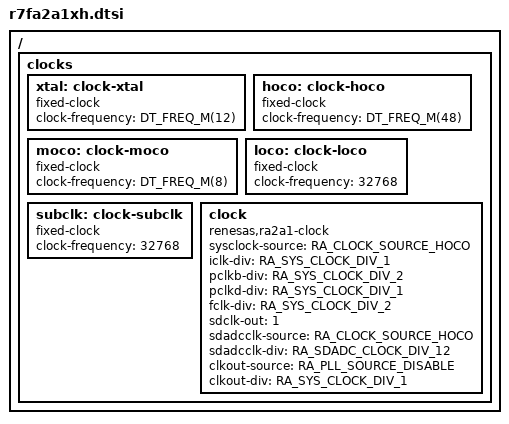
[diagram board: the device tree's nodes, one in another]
/*
 * Copyright (c) 2024 TOKITA Hiroshi
 *
 * SPDX-License-Identifier: Apache-2.0
 */

#include <zephyr/dt-bindings/clock/ra_clock.h>
#include <renesas/ra/ra2/ra2xx.dtsi>

/delete-node/ &sci2;
/delete-node/ &sci3;
/delete-node/ &gpio6;
/delete-node/ &gpio7;
/delete-node/ &gpio8;

/ {
	clocks {
		xtal: clock-xtal {
			compatible = "fixed-clock";
			clock-frequency = <DT_FREQ_M(12)>;
			#clock-cells = <0>;
		};

		hoco: clock-hoco {
			compatible = "fixed-clock";
			clock-frequency = <DT_FREQ_M(48)>;
			#clock-cells = <0>;
		};

		moco: clock-moco {
			compatible = "fixed-clock";
			clock-frequency = <DT_FREQ_M(8)>;
			#clock-cells = <0>;
		};

		loco: clock-loco {
			compatible = "fixed-clock";
			clock-frequency = <32768>;
			#clock-cells = <0>;
		};

		subclk: clock-subclk {
			compatible = "fixed-clock";
			clock-frequency = <32768>;
			#clock-cells = <0>;
		};

		clock: clock {
			compatible = "renesas,ra2a1-clock";
			#clock-cells = <0>;

			/* System Clock */
			sysclock-source = <RA_CLOCK_SOURCE_HOCO>;
			iclk-div = <RA_SYS_CLOCK_DIV_1>;
			pclkb-div = <RA_SYS_CLOCK_DIV_2>;
			pclkd-div = <RA_SYS_CLOCK_DIV_1>;
			fclk-div = <RA_SYS_CLOCK_DIV_2>;
			sdclk-out = <1>;

			sdadcclk-source = <RA_CLOCK_SOURCE_HOCO>;
			sdadcclk-div = <RA_SDADC_CLOCK_DIV_12>;
			clkout-source = <RA_PLL_SOURCE_DISABLE>;
			clkout-div = <RA_SYS_CLOCK_DIV_1>;
		};
	};
};
